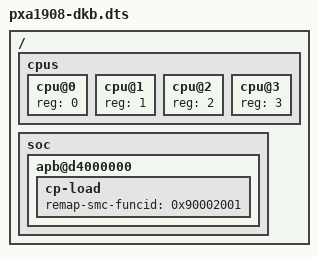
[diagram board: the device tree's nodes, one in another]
/*
 *  Copyright (C) 2014 Marvell Technology Group Ltd.
 *  Author: Dongjiu Geng <djgeng@marvell.com>
 *
 *  This program is free software; you can redistribute it and/or modify
 *  it under the terms of the GNU General Public License version 2 as
 *  publishhed by the Free Software Foundation.
 */

#include "../../../arm64/boot/dts/pxa1908-dkb.dts"

/ {
	cpus {
		#address-cells = <1>;
		#size-cells = <0>;

		cpu@0 {
			reg = <0>;
		};
		cpu@1 {
			reg = <1>;
		};
		cpu@2 {
			reg = <2>;
		};
		cpu@3 {
			reg = <3>;
		};
	};

	soc {
		apb@d4000000 {	/* APB */

			cp-load {
				remap-smc-funcid = <0x90002001>;
			};
		};
	};
};
